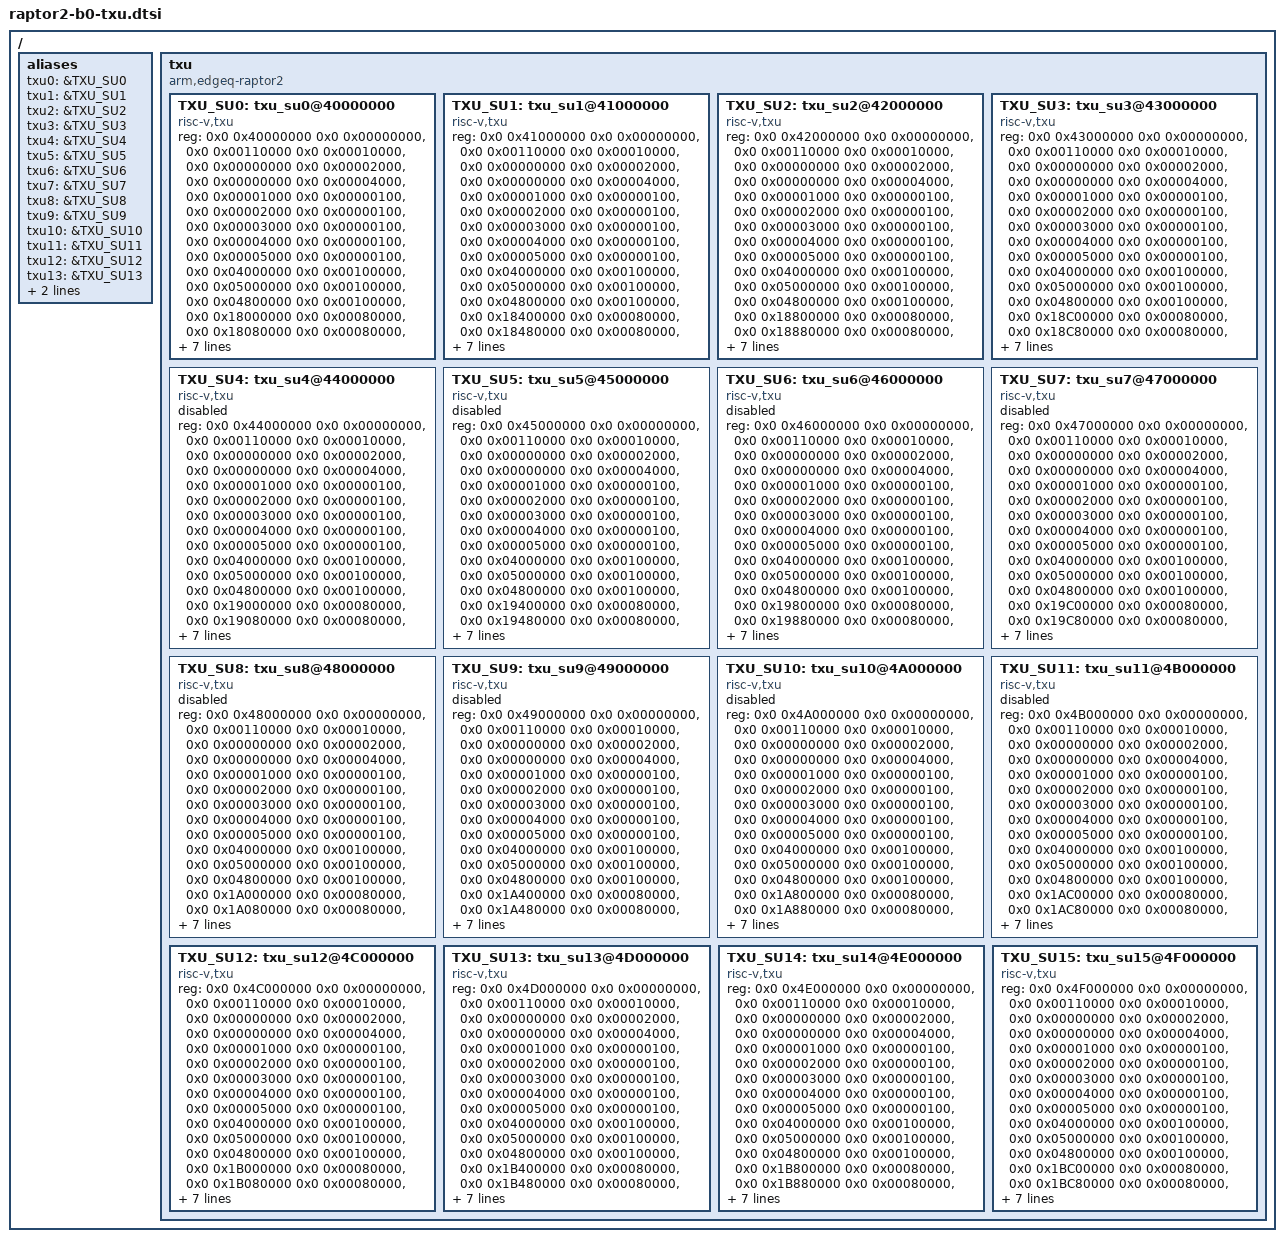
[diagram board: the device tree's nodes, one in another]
// SPDX-License-Identifier: GPL-2.0
/*
 * EdgeQ Inc.
 *
 * EdgeQ Raptor2 TXU DTS
 */

/ {
	aliases {
		txu0 = &TXU_SU0;
		txu1 = &TXU_SU1;
		txu2 = &TXU_SU2;
		txu3 = &TXU_SU3;
		txu4 = &TXU_SU4;
		txu5 = &TXU_SU5;
		txu6 = &TXU_SU6;
		txu7 = &TXU_SU7;
		txu8 = &TXU_SU8;
		txu9 = &TXU_SU9;
		txu10 = &TXU_SU10;
		txu11 = &TXU_SU11;
		txu12 = &TXU_SU12;
		txu13 = &TXU_SU13;
		txu14 = &TXU_SU14;
		txu15 = &TXU_SU15;
	};

	txu {
		compatible = "arm,edgeq-raptor2";
		#address-cells = <2>;
		#size-cells = <2>;

		TXU_SU0: txu_su0@40000000 {
			compatible = "risc-v,txu";
			device_type = "su";
			#address-cells = <2>;
			#size-cells = <2>;
			ranges;
			reg =	<0x0 0x40000000 0x0 0x00000000>,
				<0x0 0x00110000 0x0 0x00010000>,
				<0x0 0x00000000 0x0 0x00002000>,
				<0x0 0x00000000 0x0 0x00004000>,
				<0x0 0x00001000 0x0 0x00000100>,
				<0x0 0x00002000 0x0 0x00000100>,
				<0x0 0x00003000 0x0 0x00000100>,
				<0x0 0x00004000 0x0 0x00000100>,
				<0x0 0x00005000 0x0 0x00000100>,
				<0x0 0x04000000 0x0 0x00100000>,
				<0x0 0x05000000 0x0 0x00100000>,
				<0x0 0x04800000 0x0 0x00100000>,
				<0x0 0x18000000 0x0 0x00080000>,
				<0x0 0x18080000 0x0 0x00080000>,
				<0x0 0x00000000 0x0 0x00004000>,
				<0x0 0x00080000 0x0 0x00010000>,
				<0x0 0x06000000 0x0 0x00040000>,
				<0x0 0x1CE40000 0x0 0x00040000>;
			reg-names = "sudev_base", "cpu", "d-cache", "i-cache", "suinfo_offset",
			"suconf_offset", "suau_offset", "sustats_offset", "sudbg_offset",
			"lmem_addr_local_wb", "lmem_addr_local_unc", "lmem_addr_local_wt",
			"lmem_e1", "lmem_e1_b2", "ilmoffs", "dlmoffs", "ilm_cluster_local",
			"ilm_cluster_cnoc";
			enable-method = "reset-vector";
			sudev = <&SUDEV>;
			sumem = <&SUMEM>;
			status = "okay";
		};

		TXU_SU1: txu_su1@41000000 {
			compatible = "risc-v,txu";
			device_type = "su";
			#address-cells = <2>;
			#size-cells = <2>;
			ranges;
			reg =	<0x0 0x41000000 0x0 0x00000000>,
				<0x0 0x00110000 0x0 0x00010000>,
				<0x0 0x00000000 0x0 0x00002000>,
				<0x0 0x00000000 0x0 0x00004000>,
				<0x0 0x00001000 0x0 0x00000100>,
				<0x0 0x00002000 0x0 0x00000100>,
				<0x0 0x00003000 0x0 0x00000100>,
				<0x0 0x00004000 0x0 0x00000100>,
				<0x0 0x00005000 0x0 0x00000100>,
				<0x0 0x04000000 0x0 0x00100000>,
				<0x0 0x05000000 0x0 0x00100000>,
				<0x0 0x04800000 0x0 0x00100000>,
				<0x0 0x18400000 0x0 0x00080000>,
				<0x0 0x18480000 0x0 0x00080000>,
				<0x0 0x00000000 0x0 0x00004000>,
				<0x0 0x00080000 0x0 0x00010000>,
				<0x0 0x06000000 0x0 0x00040000>,
				<0x0 0x1CE40000 0x0 0x00040000>;
			reg-names = "sudev_base", "cpu", "d-cache", "i-cache", "suinfo_offset",
			"suconf_offset", "suau_offset", "sustats_offset", "sudbg_offset",
			"lmem_addr_local_wb", "lmem_addr_local_unc", "lmem_addr_local_wt",
			"lmem_e1", "lmem_e1_b2", "ilmoffs", "dlmoffs", "ilm_cluster_local",
			"ilm_cluster_cnoc";
			enable-method = "reset-vector";
			sudev = <&SUDEV>;
			sumem = <&SUMEM>;
			status = "okay";
		};

		TXU_SU2: txu_su2@42000000 {
			compatible = "risc-v,txu";
			device_type = "su";
			#address-cells = <2>;
			#size-cells = <2>;
			ranges;
			reg =	<0x0 0x42000000 0x0 0x00000000>,
				<0x0 0x00110000 0x0 0x00010000>,
				<0x0 0x00000000 0x0 0x00002000>,
				<0x0 0x00000000 0x0 0x00004000>,
				<0x0 0x00001000 0x0 0x00000100>,
				<0x0 0x00002000 0x0 0x00000100>,
				<0x0 0x00003000 0x0 0x00000100>,
				<0x0 0x00004000 0x0 0x00000100>,
				<0x0 0x00005000 0x0 0x00000100>,
				<0x0 0x04000000 0x0 0x00100000>,
				<0x0 0x05000000 0x0 0x00100000>,
				<0x0 0x04800000 0x0 0x00100000>,
				<0x0 0x18800000 0x0 0x00080000>,
				<0x0 0x18880000 0x0 0x00080000>,
				<0x0 0x00000000 0x0 0x00004000>,
				<0x0 0x00080000 0x0 0x00010000>,
				<0x0 0x06000000 0x0 0x00040000>,
				<0x0 0x1CE40000 0x0 0x00040000>;
			reg-names = "sudev_base", "cpu", "d-cache", "i-cache", "suinfo_offset",
			"suconf_offset", "suau_offset", "sustats_offset", "sudbg_offset",
			"lmem_addr_local_wb", "lmem_addr_local_unc", "lmem_addr_local_wt",
			"lmem_e1", "lmem_e1_b2", "ilmoffs", "dlmoffs", "ilm_cluster_local",
			"ilm_cluster_cnoc";
			enable-method = "reset-vector";
			sudev = <&SUDEV>;
			sumem = <&SUMEM>;
			status = "okay";
		};

		TXU_SU3: txu_su3@43000000 {
			compatible = "risc-v,txu";
			device_type = "su";
			#address-cells = <2>;
			#size-cells = <2>;
			ranges;
			reg =	<0x0 0x43000000 0x0 0x00000000>,
				<0x0 0x00110000 0x0 0x00010000>,
				<0x0 0x00000000 0x0 0x00002000>,
				<0x0 0x00000000 0x0 0x00004000>,
				<0x0 0x00001000 0x0 0x00000100>,
				<0x0 0x00002000 0x0 0x00000100>,
				<0x0 0x00003000 0x0 0x00000100>,
				<0x0 0x00004000 0x0 0x00000100>,
				<0x0 0x00005000 0x0 0x00000100>,
				<0x0 0x04000000 0x0 0x00100000>,
				<0x0 0x05000000 0x0 0x00100000>,
				<0x0 0x04800000 0x0 0x00100000>,
				<0x0 0x18C00000 0x0 0x00080000>,
				<0x0 0x18C80000 0x0 0x00080000>,
				<0x0 0x00000000 0x0 0x00004000>,
				<0x0 0x00080000 0x0 0x00010000>,
				<0x0 0x06000000 0x0 0x00040000>,
				<0x0 0x1CE40000 0x0 0x00040000>;
			reg-names = "sudev_base", "cpu", "d-cache", "i-cache", "suinfo_offset",
			"suconf_offset", "suau_offset", "sustats_offset", "sudbg_offset",
			"lmem_addr_local_wb", "lmem_addr_local_unc", "lmem_addr_local_wt",
			"lmem_e1", "lmem_e1_b2", "ilmoffs", "dlmoffs", "ilm_cluster_local",
			"ilm_cluster_cnoc";
			enable-method = "reset-vector";
			sudev = <&SUDEV>;
			sumem = <&SUMEM>;
			status = "okay";
		};

		TXU_SU4: txu_su4@44000000 {
			compatible = "risc-v,txu";
			device_type = "su";
			#address-cells = <2>;
			#size-cells = <2>;
			ranges;
			reg =	<0x0 0x44000000 0x0 0x00000000>,
				<0x0 0x00110000 0x0 0x00010000>,
				<0x0 0x00000000 0x0 0x00002000>,
				<0x0 0x00000000 0x0 0x00004000>,
				<0x0 0x00001000 0x0 0x00000100>,
				<0x0 0x00002000 0x0 0x00000100>,
				<0x0 0x00003000 0x0 0x00000100>,
				<0x0 0x00004000 0x0 0x00000100>,
				<0x0 0x00005000 0x0 0x00000100>,
				<0x0 0x04000000 0x0 0x00100000>,
				<0x0 0x05000000 0x0 0x00100000>,
				<0x0 0x04800000 0x0 0x00100000>,
				<0x0 0x19000000 0x0 0x00080000>,
				<0x0 0x19080000 0x0 0x00080000>,
				<0x0 0x00000000 0x0 0x00004000>,
				<0x0 0x00080000 0x0 0x00010000>,
				<0x0 0x06000000 0x0 0x00040000>,
				<0x0 0x1CE80000 0x0 0x00040000>;
			reg-names = "sudev_base", "cpu", "d-cache", "i-cache", "suinfo_offset",
			"suconf_offset", "suau_offset", "sustats_offset", "sudbg_offset",
			"lmem_addr_local_wb", "lmem_addr_local_unc", "lmem_addr_local_wt",
			"lmem_e1", "lmem_e1_b2", "ilmoffs", "dlmoffs", "ilm_cluster_local",
			"ilm_cluster_cnoc";
			enable-method = "reset-vector";
			sudev = <&SUDEV>;
			sumem = <&SUMEM>;
			status = "disabled";
		};

		TXU_SU5: txu_su5@45000000 {
			compatible = "risc-v,txu";
			device_type = "su";
			#address-cells = <2>;
			#size-cells = <2>;
			ranges;
			reg =	<0x0 0x45000000 0x0 0x00000000>,
				<0x0 0x00110000 0x0 0x00010000>,
				<0x0 0x00000000 0x0 0x00002000>,
				<0x0 0x00000000 0x0 0x00004000>,
				<0x0 0x00001000 0x0 0x00000100>,
				<0x0 0x00002000 0x0 0x00000100>,
				<0x0 0x00003000 0x0 0x00000100>,
				<0x0 0x00004000 0x0 0x00000100>,
				<0x0 0x00005000 0x0 0x00000100>,
				<0x0 0x04000000 0x0 0x00100000>,
				<0x0 0x05000000 0x0 0x00100000>,
				<0x0 0x04800000 0x0 0x00100000>,
				<0x0 0x19400000 0x0 0x00080000>,
				<0x0 0x19480000 0x0 0x00080000>,
				<0x0 0x00000000 0x0 0x00004000>,
				<0x0 0x00080000 0x0 0x00010000>,
				<0x0 0x06000000 0x0 0x00040000>,
				<0x0 0x1CE80000 0x0 0x00040000>;
			reg-names = "sudev_base", "cpu", "d-cache", "i-cache", "suinfo_offset",
			"suconf_offset", "suau_offset", "sustats_offset", "sudbg_offset",
			"lmem_addr_local_wb", "lmem_addr_local_unc", "lmem_addr_local_wt",
			"lmem_e1", "lmem_e1_b2", "ilmoffs", "dlmoffs", "ilm_cluster_local",
			"ilm_cluster_cnoc";
			enable-method = "reset-vector";
			sudev = <&SUDEV>;
			sumem = <&SUMEM>;
			status = "disabled";
		};

		TXU_SU6: txu_su6@46000000 {
			compatible = "risc-v,txu";
			device_type = "su";
			#address-cells = <2>;
			#size-cells = <2>;
			ranges;
			reg =	<0x0 0x46000000 0x0 0x00000000>,
				<0x0 0x00110000 0x0 0x00010000>,
				<0x0 0x00000000 0x0 0x00002000>,
				<0x0 0x00000000 0x0 0x00004000>,
				<0x0 0x00001000 0x0 0x00000100>,
				<0x0 0x00002000 0x0 0x00000100>,
				<0x0 0x00003000 0x0 0x00000100>,
				<0x0 0x00004000 0x0 0x00000100>,
				<0x0 0x00005000 0x0 0x00000100>,
				<0x0 0x04000000 0x0 0x00100000>,
				<0x0 0x05000000 0x0 0x00100000>,
				<0x0 0x04800000 0x0 0x00100000>,
				<0x0 0x19800000 0x0 0x00080000>,
				<0x0 0x19880000 0x0 0x00080000>,
				<0x0 0x00000000 0x0 0x00004000>,
				<0x0 0x00080000 0x0 0x00010000>,
				<0x0 0x06000000 0x0 0x00040000>,
				<0x0 0x1CE80000 0x0 0x00040000>;
			reg-names = "sudev_base", "cpu", "d-cache", "i-cache", "suinfo_offset",
			"suconf_offset", "suau_offset", "sustats_offset", "sudbg_offset",
			"lmem_addr_local_wb", "lmem_addr_local_unc", "lmem_addr_local_wt",
			"lmem_e1", "lmem_e1_b2", "ilmoffs", "dlmoffs", "ilm_cluster_local",
			"ilm_cluster_cnoc";
			enable-method = "reset-vector";
			sudev = <&SUDEV>;
			sumem = <&SUMEM>;
			status = "disabled";
		};

		TXU_SU7: txu_su7@47000000 {
			compatible = "risc-v,txu";
			device_type = "su";
			#address-cells = <2>;
			#size-cells = <2>;
			ranges;
			reg =	<0x0 0x47000000 0x0 0x00000000>,
				<0x0 0x00110000 0x0 0x00010000>,
				<0x0 0x00000000 0x0 0x00002000>,
				<0x0 0x00000000 0x0 0x00004000>,
				<0x0 0x00001000 0x0 0x00000100>,
				<0x0 0x00002000 0x0 0x00000100>,
				<0x0 0x00003000 0x0 0x00000100>,
				<0x0 0x00004000 0x0 0x00000100>,
				<0x0 0x00005000 0x0 0x00000100>,
				<0x0 0x04000000 0x0 0x00100000>,
				<0x0 0x05000000 0x0 0x00100000>,
				<0x0 0x04800000 0x0 0x00100000>,
				<0x0 0x19C00000 0x0 0x00080000>,
				<0x0 0x19C80000 0x0 0x00080000>,
				<0x0 0x00000000 0x0 0x00004000>,
				<0x0 0x00080000 0x0 0x00010000>,
				<0x0 0x06000000 0x0 0x00040000>,
				<0x0 0x1CE80000 0x0 0x00040000>;
			reg-names = "sudev_base", "cpu", "d-cache", "i-cache", "suinfo_offset",
			"suconf_offset", "suau_offset", "sustats_offset", "sudbg_offset",
			"lmem_addr_local_wb", "lmem_addr_local_unc", "lmem_addr_local_wt",
			"lmem_e1", "lmem_e1_b2", "ilmoffs", "dlmoffs", "ilm_cluster_local",
			"ilm_cluster_cnoc";
			enable-method = "reset-vector";
			sudev = <&SUDEV>;
			sumem = <&SUMEM>;
			status = "disabled";
		};

		TXU_SU8: txu_su8@48000000 {
			compatible = "risc-v,txu";
			device_type = "su";
			#address-cells = <2>;
			#size-cells = <2>;
			ranges;
			reg =	<0x0 0x48000000 0x0 0x00000000>,
				<0x0 0x00110000 0x0 0x00010000>,
				<0x0 0x00000000 0x0 0x00002000>,
				<0x0 0x00000000 0x0 0x00004000>,
				<0x0 0x00001000 0x0 0x00000100>,
				<0x0 0x00002000 0x0 0x00000100>,
				<0x0 0x00003000 0x0 0x00000100>,
				<0x0 0x00004000 0x0 0x00000100>,
				<0x0 0x00005000 0x0 0x00000100>,
				<0x0 0x04000000 0x0 0x00100000>,
				<0x0 0x05000000 0x0 0x00100000>,
				<0x0 0x04800000 0x0 0x00100000>,
				<0x0 0x1A000000 0x0 0x00080000>,
				<0x0 0x1A080000 0x0 0x00080000>,
				<0x0 0x00000000 0x0 0x00004000>,
				<0x0 0x00080000 0x0 0x00010000>,
				<0x0 0x06000000 0x0 0x00040000>,
				<0x0 0x1CEC0000 0x0 0x00040000>;
			reg-names = "sudev_base", "cpu", "d-cache", "i-cache", "suinfo_offset",
			"suconf_offset", "suau_offset", "sustats_offset", "sudbg_offset",
			"lmem_addr_local_wb", "lmem_addr_local_unc", "lmem_addr_local_wt",
			"lmem_e1", "lmem_e1_b2", "ilmoffs", "dlmoffs", "ilm_cluster_local",
			"ilm_cluster_cnoc";
			enable-method = "reset-vector";
			sudev = <&SUDEV>;
			sumem = <&SUMEM>;
			status = "disabled";
		};

		TXU_SU9: txu_su9@49000000 {
			compatible = "risc-v,txu";
			device_type = "su";
			#address-cells = <2>;
			#size-cells = <2>;
			ranges;
			reg =	<0x0 0x49000000 0x0 0x00000000>,
				<0x0 0x00110000 0x0 0x00010000>,
				<0x0 0x00000000 0x0 0x00002000>,
				<0x0 0x00000000 0x0 0x00004000>,
				<0x0 0x00001000 0x0 0x00000100>,
				<0x0 0x00002000 0x0 0x00000100>,
				<0x0 0x00003000 0x0 0x00000100>,
				<0x0 0x00004000 0x0 0x00000100>,
				<0x0 0x00005000 0x0 0x00000100>,
				<0x0 0x04000000 0x0 0x00100000>,
				<0x0 0x05000000 0x0 0x00100000>,
				<0x0 0x04800000 0x0 0x00100000>,
				<0x0 0x1A400000 0x0 0x00080000>,
				<0x0 0x1A480000 0x0 0x00080000>,
				<0x0 0x00000000 0x0 0x00004000>,
				<0x0 0x00080000 0x0 0x00010000>,
				<0x0 0x06000000 0x0 0x00040000>,
				<0x0 0x1CEC0000 0x0 0x00040000>;
			reg-names = "sudev_base", "cpu", "d-cache", "i-cache", "suinfo_offset",
			"suconf_offset", "suau_offset", "sustats_offset", "sudbg_offset",
			"lmem_addr_local_wb", "lmem_addr_local_unc", "lmem_addr_local_wt",
			"lmem_e1", "lmem_e1_b2", "ilmoffs", "dlmoffs", "ilm_cluster_local",
			"ilm_cluster_cnoc";
			enable-method = "reset-vector";
			sudev = <&SUDEV>;
			sumem = <&SUMEM>;
			status = "disabled";
		};

		TXU_SU10: txu_su10@4A000000 {
			compatible = "risc-v,txu";
			device_type = "su";
			#address-cells = <2>;
			#size-cells = <2>;
			ranges;
			reg =	<0x0 0x4A000000 0x0 0x00000000>,
				<0x0 0x00110000 0x0 0x00010000>,
				<0x0 0x00000000 0x0 0x00002000>,
				<0x0 0x00000000 0x0 0x00004000>,
				<0x0 0x00001000 0x0 0x00000100>,
				<0x0 0x00002000 0x0 0x00000100>,
				<0x0 0x00003000 0x0 0x00000100>,
				<0x0 0x00004000 0x0 0x00000100>,
				<0x0 0x00005000 0x0 0x00000100>,
				<0x0 0x04000000 0x0 0x00100000>,
				<0x0 0x05000000 0x0 0x00100000>,
				<0x0 0x04800000 0x0 0x00100000>,
				<0x0 0x1A800000 0x0 0x00080000>,
				<0x0 0x1A880000 0x0 0x00080000>,
				<0x0 0x00000000 0x0 0x00004000>,
				<0x0 0x00080000 0x0 0x00010000>,
				<0x0 0x06000000 0x0 0x00040000>,
				<0x0 0x1CEC0000 0x0 0x00040000>;
			reg-names = "sudev_base", "cpu", "d-cache", "i-cache", "suinfo_offset",
			"suconf_offset", "suau_offset", "sustats_offset", "sudbg_offset",
			"lmem_addr_local_wb", "lmem_addr_local_unc", "lmem_addr_local_wt",
			"lmem_e1", "lmem_e1_b2", "ilmoffs", "dlmoffs", "ilm_cluster_local",
			"ilm_cluster_cnoc";
			enable-method = "reset-vector";
			sudev = <&SUDEV>;
			sumem = <&SUMEM>;
			status = "disabled";
		};

		TXU_SU11: txu_su11@4B000000 {
			compatible = "risc-v,txu";
			device_type = "su";
			#address-cells = <2>;
			#size-cells = <2>;
			ranges;
			reg =	<0x0 0x4B000000 0x0 0x00000000>,
				<0x0 0x00110000 0x0 0x00010000>,
				<0x0 0x00000000 0x0 0x00002000>,
				<0x0 0x00000000 0x0 0x00004000>,
				<0x0 0x00001000 0x0 0x00000100>,
				<0x0 0x00002000 0x0 0x00000100>,
				<0x0 0x00003000 0x0 0x00000100>,
				<0x0 0x00004000 0x0 0x00000100>,
				<0x0 0x00005000 0x0 0x00000100>,
				<0x0 0x04000000 0x0 0x00100000>,
				<0x0 0x05000000 0x0 0x00100000>,
				<0x0 0x04800000 0x0 0x00100000>,
				<0x0 0x1AC00000 0x0 0x00080000>,
				<0x0 0x1AC80000 0x0 0x00080000>,
				<0x0 0x00000000 0x0 0x00004000>,
				<0x0 0x00080000 0x0 0x00010000>,
				<0x0 0x06000000 0x0 0x00040000>,
				<0x0 0x1CEC0000 0x0 0x00040000>;
			reg-names = "sudev_base", "cpu", "d-cache", "i-cache", "suinfo_offset",
			"suconf_offset", "suau_offset", "sustats_offset", "sudbg_offset",
			"lmem_addr_local_wb", "lmem_addr_local_unc", "lmem_addr_local_wt",
			"lmem_e1", "lmem_e1_b2", "ilmoffs", "dlmoffs", "ilm_cluster_local",
			"ilm_cluster_cnoc";
			enable-method = "reset-vector";
			sudev = <&SUDEV>;
			sumem = <&SUMEM>;
			status = "disabled";
		};

		TXU_SU12: txu_su12@4C000000 {
			compatible = "risc-v,txu";
			device_type = "su";
			#address-cells = <2>;
			#size-cells = <2>;
			ranges;
			reg =	<0x0 0x4C000000 0x0 0x00000000>,
				<0x0 0x00110000 0x0 0x00010000>,
				<0x0 0x00000000 0x0 0x00002000>,
				<0x0 0x00000000 0x0 0x00004000>,
				<0x0 0x00001000 0x0 0x00000100>,
				<0x0 0x00002000 0x0 0x00000100>,
				<0x0 0x00003000 0x0 0x00000100>,
				<0x0 0x00004000 0x0 0x00000100>,
				<0x0 0x00005000 0x0 0x00000100>,
				<0x0 0x04000000 0x0 0x00100000>,
				<0x0 0x05000000 0x0 0x00100000>,
				<0x0 0x04800000 0x0 0x00100000>,
				<0x0 0x1B000000 0x0 0x00080000>,
				<0x0 0x1B080000 0x0 0x00080000>,
				<0x0 0x00000000 0x0 0x00004000>,
				<0x0 0x00080000 0x0 0x00010000>,
				<0x0 0x06000000 0x0 0x00040000>,
				<0x0 0x1CF00000 0x0 0x00040000>;
			reg-names = "sudev_base", "cpu", "d-cache", "i-cache", "suinfo_offset",
			"suconf_offset", "suau_offset", "sustats_offset", "sudbg_offset",
			"lmem_addr_local_wb", "lmem_addr_local_unc", "lmem_addr_local_wt",
			"lmem_e1", "lmem_e1_b2", "ilmoffs", "dlmoffs", "ilm_cluster_local",
			"ilm_cluster_cnoc";
			enable-method = "reset-vector";
			sudev = <&SUDEV>;
			sumem = <&SUMEM>;
			status = "okay";
		};

		TXU_SU13: txu_su13@4D000000 {
			compatible = "risc-v,txu";
			device_type = "su";
			#address-cells = <2>;
			#size-cells = <2>;
			ranges;
			reg =	<0x0 0x4D000000 0x0 0x00000000>,
				<0x0 0x00110000 0x0 0x00010000>,
				<0x0 0x00000000 0x0 0x00002000>,
				<0x0 0x00000000 0x0 0x00004000>,
				<0x0 0x00001000 0x0 0x00000100>,
				<0x0 0x00002000 0x0 0x00000100>,
				<0x0 0x00003000 0x0 0x00000100>,
				<0x0 0x00004000 0x0 0x00000100>,
				<0x0 0x00005000 0x0 0x00000100>,
				<0x0 0x04000000 0x0 0x00100000>,
				<0x0 0x05000000 0x0 0x00100000>,
				<0x0 0x04800000 0x0 0x00100000>,
				<0x0 0x1B400000 0x0 0x00080000>,
				<0x0 0x1B480000 0x0 0x00080000>,
				<0x0 0x00000000 0x0 0x00004000>,
				<0x0 0x00080000 0x0 0x00010000>,
				<0x0 0x06000000 0x0 0x00040000>,
				<0x0 0x1CF00000 0x0 0x00040000>;
			reg-names = "sudev_base", "cpu", "d-cache", "i-cache", "suinfo_offset",
			"suconf_offset", "suau_offset", "sustats_offset", "sudbg_offset",
			"lmem_addr_local_wb", "lmem_addr_local_unc", "lmem_addr_local_wt",
			"lmem_e1", "lmem_e1_b2", "ilmoffs", "dlmoffs", "ilm_cluster_local",
			"ilm_cluster_cnoc";
			enable-method = "reset-vector";
			sudev = <&SUDEV>;
			sumem = <&SUMEM>;
			status = "okay";
		};

		TXU_SU14: txu_su14@4E000000 {
			compatible = "risc-v,txu";
			device_type = "su";
			#address-cells = <2>;
			#size-cells = <2>;
			ranges;
			reg =	<0x0 0x4E000000 0x0 0x00000000>,
				<0x0 0x00110000 0x0 0x00010000>,
				<0x0 0x00000000 0x0 0x00002000>,
				<0x0 0x00000000 0x0 0x00004000>,
				<0x0 0x00001000 0x0 0x00000100>,
				<0x0 0x00002000 0x0 0x00000100>,
				<0x0 0x00003000 0x0 0x00000100>,
				<0x0 0x00004000 0x0 0x00000100>,
				<0x0 0x00005000 0x0 0x00000100>,
				<0x0 0x04000000 0x0 0x00100000>,
				<0x0 0x05000000 0x0 0x00100000>,
				<0x0 0x04800000 0x0 0x00100000>,
				<0x0 0x1B800000 0x0 0x00080000>,
				<0x0 0x1B880000 0x0 0x00080000>,
				<0x0 0x00000000 0x0 0x00004000>,
				<0x0 0x00080000 0x0 0x00010000>,
				<0x0 0x06000000 0x0 0x00040000>,
				<0x0 0x1CF00000 0x0 0x00040000>;
			reg-names = "sudev_base", "cpu", "d-cache", "i-cache", "suinfo_offset",
			"suconf_offset", "suau_offset", "sustats_offset", "sudbg_offset",
			"lmem_addr_local_wb", "lmem_addr_local_unc", "lmem_addr_local_wt",
			"lmem_e1", "lmem_e1_b2", "ilmoffs", "dlmoffs", "ilm_cluster_local",
			"ilm_cluster_cnoc";
			enable-method = "reset-vector";
			sudev = <&SUDEV>;
			sumem = <&SUMEM>;
			status = "okay";
		};

		TXU_SU15: txu_su15@4F000000 {
			compatible = "risc-v,txu";
			device_type = "su";
			#address-cells = <2>;
			#size-cells = <2>;
			ranges;
			reg =	<0x0 0x4F000000 0x0 0x00000000>,
				<0x0 0x00110000 0x0 0x00010000>,
				<0x0 0x00000000 0x0 0x00002000>,
				<0x0 0x00000000 0x0 0x00004000>,
				<0x0 0x00001000 0x0 0x00000100>,
				<0x0 0x00002000 0x0 0x00000100>,
				<0x0 0x00003000 0x0 0x00000100>,
				<0x0 0x00004000 0x0 0x00000100>,
				<0x0 0x00005000 0x0 0x00000100>,
				<0x0 0x04000000 0x0 0x00100000>,
				<0x0 0x05000000 0x0 0x00100000>,
				<0x0 0x04800000 0x0 0x00100000>,
				<0x0 0x1BC00000 0x0 0x00080000>,
				<0x0 0x1BC80000 0x0 0x00080000>,
				<0x0 0x00000000 0x0 0x00004000>,
				<0x0 0x00080000 0x0 0x00010000>,
				<0x0 0x06000000 0x0 0x00040000>,
				<0x0 0x1CF00000 0x0 0x00040000>;
			reg-names = "sudev_base", "cpu", "d-cache", "i-cache", "suinfo_offset",
			"suconf_offset", "suau_offset", "sustats_offset", "sudbg_offset",
			"lmem_addr_local_wb", "lmem_addr_local_unc", "lmem_addr_local_wt",
			"lmem_e1", "lmem_e1_b2", "ilmoffs", "dlmoffs", "ilm_cluster_local",
			"ilm_cluster_cnoc";
			enable-method = "reset-vector";
			sudev = <&SUDEV>;
			sumem = <&SUMEM>;
			status = "okay";
		};

	};
};
